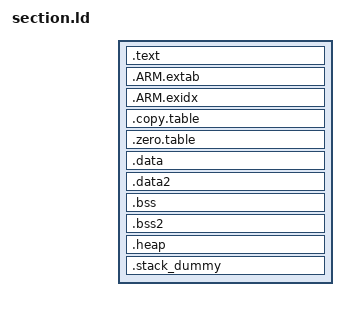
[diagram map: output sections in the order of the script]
ENTRY(Start_Handler)

SECTIONS
{
	.text :
	{
		KEEP(*(.vector))
		*(.text*)

		KEEP(*(.init))
		KEEP(*(.fini))

		/* .ctors */
		*crtbegin.o(.ctors)
		*crtbegin?.o(.ctors)
		*(EXCLUDE_FILE(*crtend?.o *crtend.o) .ctors)
		*(SORT(.ctors.*))
		*(.ctors)

		/* .dtors */
 		*crtbegin.o(.dtors)
 		*crtbegin?.o(.dtors)
 		*(EXCLUDE_FILE(*crtend?.o *crtend.o) .dtors)
 		*(SORT(.dtors.*))
 		*(.dtors)

		*(.rodata*)

		KEEP(*(.eh_frame*))
	} > FLASH

	.ARM.extab : 
	{
		*(.ARM.extab* .gnu.linkonce.armextab.*)
	} > FLASH

	__exidx_start = .;
	.ARM.exidx :
	{
		*(.ARM.exidx* .gnu.linkonce.armexidx.*)
	} > FLASH
	__exidx_end = .;

	.copy.table :
	{
		. = ALIGN(4);
		__copy_table_start__ = .;
		LONG (__etext)
		LONG (__data_start__)
		LONG (__data_end__ - __data_start__)
		LONG (__etext2)
		LONG (__data2_start__)
		LONG (__data2_end__ - __data2_start__)
		__copy_table_end__ = .;
	} > FLASH

	.zero.table :
	{
		. = ALIGN(4);
		__zero_table_start__ = .;
		LONG (__bss_start__)
		LONG (__bss_end__ - __bss_start__)
		LONG (__bss2_start__)
		LONG (__bss2_end__ - __bss2_start__)
		__zero_table_end__ = .;
	} > FLASH

	__etext = ALIGN (4);

	.data : AT (__etext)
	{
		__data_start__ = .;
		*(vtable)
		*(.data*)
		__data_end__ = .;

	} > RAM

	__etext2 = __etext + ALIGN (SIZEOF(.data), 4);

	.data2 : AT (__etext2)
	{
		__data2_start__ = .;

		. = ALIGN(4);
		/* preinit data */
		PROVIDE_HIDDEN (__preinit_array_start = .);
		KEEP(*(.preinit_array))
		PROVIDE_HIDDEN (__preinit_array_end = .);

		. = ALIGN(4);
		/* init data */
		PROVIDE_HIDDEN (__init_array_start = .);
		KEEP(*(SORT(.init_array.*)))
		KEEP(*(.init_array))
		PROVIDE_HIDDEN (__init_array_end = .);


		. = ALIGN(4);
		/* finit data */
		PROVIDE_HIDDEN (__fini_array_start = .);
		KEEP(*(SORT(.fini_array.*)))
		KEEP(*(.fini_array))
		PROVIDE_HIDDEN (__fini_array_end = .);

		KEEP(*(.jcr*))
		. = ALIGN(4);
		/* All data end */
		__data2_end__ = .;

	} > RAM2

	.bss :
	{
		. = ALIGN(4);
		__bss_start__ = .;
		*(.bss*)
		. = ALIGN(4);
		__bss_end__ = .;
	} > RAM

	.bss2 :
	{
		. = ALIGN(4);
		__bss2_start__ = .;
		*(COMMON)
		. = ALIGN(4);
		__bss2_end__ = .;
	} > RAM2
	
	.heap (COPY):
	{
		__end__ = .;
		PROVIDE(end = .);
		*(.heap*)
		__HeapLimit = .;
	} > RAM

	.stack_dummy (COPY):
	{
		*(.stack*)
	} > RAM
	
}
